# AT90PWM81 device description
Architecture: AVR8; Family: megaAVR
Registers are 8-bit, access not given, no defined reset value unless marked. A register's access mark holds for its fields unless they carry their own. Offsets are from the block's base; [hi:lo] are bit positions; {n}, {i} and the like mark numbered series.

## PORTB — I/O Port
Instances: PORTB 0x00
0x23 PINB — Port B Input Pins
0x24 DDRB — Port B Data Direction Register
0x25 PORTB — Port B Data Register

## PORTD — I/O Port
Instances: PORTD 0x00
0x29 PIND — Port D Input Pins
0x2A DDRD — Port D Data Direction Register
0x2B PORTD — Port D Data Register

## PORTE — I/O Port
Instances: PORTE 0x00
0x2C PINE bits used 2:0 — Port E Input Pins
0x2D DDRE bits used 2:0 — Port E Data Direction Register
0x2E PORTE bits used 2:0 — Port E Data Register

## DAC — Digital-to-Analog Converter
Instances: DAC 0x00
0x58 DAC 16-bit — DAC Data Register
  [9:0] DACH — DAC Data Register Bits
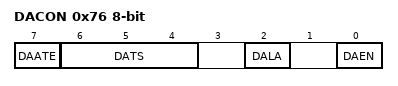
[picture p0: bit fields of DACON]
0x76 DACON — DAC Control Register
  [7] DAATE — DAC Auto Trigger Enable Bit
  [6:4] DATS — DAC Trigger Selection Bits
    0=Analog Comparator 0; 1=Analog Comparator 1; 2=External Interrupt Request 0; 3=Timer/Counter0 Compare Match A; 4=Timer/Counter0 Overflow; 5=Timer/Counter1 Compare Match B; 6=Timer/Counter1 Overflow; 7=Timer/Counter1 Capture Event
  [2] DALA — DAC Left Adjust
  [0] DAEN — DAC Enable Bit

## SPI — Serial Peripheral Interface
Instances: SPI 0x00
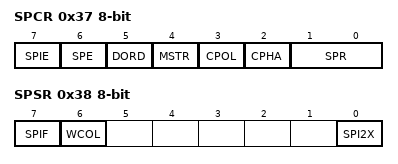
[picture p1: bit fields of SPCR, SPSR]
0x37 SPCR — SPI Control Register
  [7] SPIE — SPI Interrupt Enable
  [6] SPE — SPI Enable
  [5] DORD — Data Order
  [4] MSTR — Master/Slave Select
  [3] CPOL — Clock polarity
  [2] CPHA — Clock Phase
  [1:0] SPR — SPI Clock Rate Selects
    0=fosc/4; 1=fosc/16; 2=fosc/64; 3=fosc/128; 4=fosc/2; 5=fosc/8; 6=fosc/32; 7=fosc/64
0x38 SPSR — SPI Status Register
  [7] SPIF — SPI Interrupt Flag
  [6] WCOL — Write Collision Flag
  [0] SPI2X — Double SPI Speed Bit
0x56 SPDR — SPI Data Register
  [7:0] SPD — SPI Data bits

## WDT — Watchdog Timer
Instances: WDT 0x00
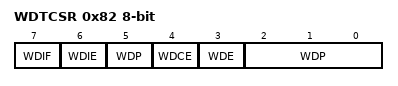
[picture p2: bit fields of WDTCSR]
0x82 WDTCSR — Watchdog Timer Control Register
  [7] WDIF — Watchdog Timeout Interrupt Flag
  [6] WDIE — Watchdog Timeout Interrupt Enable
  [4] WDCE — Watchdog Change Enable
  [3] WDE — Watch Dog Enable
  [5,2:0] WDP — Watchdog Timer Prescaler Bits
    0=Oscillator Cycles 2K; 1=Oscillator Cycles 4K; 2=Oscillator Cycles 8K; 3=Oscillator Cycles 16K; 4=Oscillator Cycles 32K; 5=Oscillator Cycles 64K; 6=Oscillator Cycles 128K; 7=Oscillator Cycles 256K; 8=Oscillator Cycles 512K; 9=Oscillator Cycles 1024K

## EXINT — External Interrupts
Instances: EXINT 0x00
0x40 EIFR — External Interrupt Flag Register
  [2:0] INTF — External Interrupt Flags
0x41 EIMSK — External Interrupt Mask Register
  [2:0] INT — External Interrupt Request 2 Enable
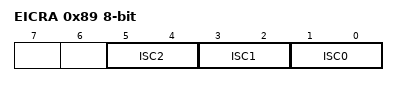
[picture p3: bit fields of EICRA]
0x89 EICRA — External Interrupt Control Register A
  [all] fields
    0=Low Level of INTX; 1=Any Logical Change of INTX; 2=Falling Edge of INTX; 3=Rising Edge of INTX
  [5:4] ISC2 — External Interrupt Sense Control Bit
  [3:2] ISC1 — External Interrupt Sense Control Bit
  [1:0] ISC0 — External Interrupt Sense Control Bit

## ADC — Analog-to-Digital Converter
Instances: ADC 0x00
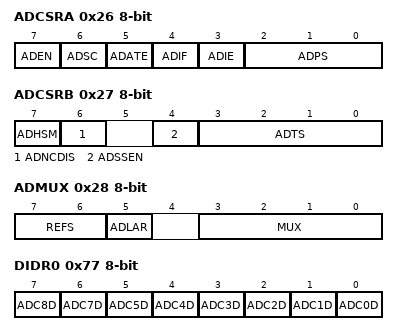
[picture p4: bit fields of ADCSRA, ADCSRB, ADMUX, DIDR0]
0x26 ADCSRA — The ADC Control and Status register
  [7] ADEN — ADC Enable
  [6] ADSC — ADC Start Conversion
  [5] ADATE — ADC Auto Trigger Enable
  [4] ADIF — ADC Interrupt Flag
  [3] ADIE — ADC Interrupt Enable
  [2:0] ADPS — ADC Prescaler Select Bits
0x27 ADCSRB — ADC Control and Status Register B
  [7] ADHSM — ADC High Speed Mode
  [6] ADNCDIS — ADC Noise Canceller Disable
  [4] ADSSEN — ADC Single Shot Enable on PSC's Synchronisation Signals
  [3:0] ADTS — ADC Auto Trigger Sources
    0=Free Running mode; 1=Analog Comparator; 2=External Interrupt Request 0; 3=Timer/Counter0 Compare Match A; 4=Timer/Counter0 Overflow; 5=Timer/Counter1 Compare Match B; 6=Timer/Counter1 Overflow; 7=Timer/Counter1 Capture Event; 8=PSC0ASY Event; 9=PSC1ASY Event; 10=PSC2ASY Event; 11=Analog comparator 1; 12=Analog comparator 2
0x28 ADMUX — The ADC multiplexer Selection Register
  [7:6] REFS — Reference Selection Bits
    0=AREF, Internal Vref turned off; 1=AVCC with external capacitor at AREF pin; 3=Internal 2.56V Voltage Reference with external capacitor at AREF pin
  [5] ADLAR — Left Adjust Result
  [3:0] MUX — Analog Channel and Gain Selection Bits
0x4C ADC 16-bit — ADC Data Register Bytes
  [15:0] ADC — ADC Data Register
0x77 DIDR0 — Digital Input Disable Register 0
  [7] ADC8D — ADC8 Digital input Disable
  [6] ADC7D — ADC7 Digital input Disable
  [n] ADC{n}D (n=0..5) — ADC{n} Digital input Disable
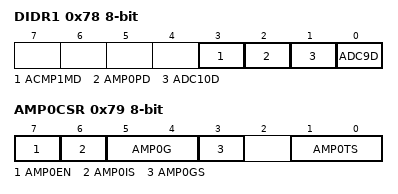
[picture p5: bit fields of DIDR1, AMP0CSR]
0x78 DIDR1 — Digital Input Disable Register 1
  [3] ACMP1MD
  [2] AMP0PD
  [1] ADC10D — ADC10 Digital input Disable
  [0] ADC9D — ADC9 Digital input Disable
0x79 AMP0CSR
  [7] AMP0EN, [6] AMP0IS, [5:4] AMP0G, [3] AMP0GS, [1:0] AMP0TS
